# pmg1s3 register map
Vendor: Infineon Technologies; Series: PMG1S3; File version: 1.0
CPU: CM0PLUS r0p1, little endian, MPU, no FPU, VTOR, 2 interrupt priority bits, 32 interrupts
Registers are 32-bit, read-write, reset 0x0 unless marked. A register's access mark holds for its fields unless they carry their own. Offsets are from the block's base; [hi:lo] are bit positions; {n}, {i} and the like mark numbered series; 'fields as' and 'values as' point back to an identical list; <NAME> marks a mode.

## SCB0 — Serial Communications Block (SPI/UART/I2C)
Base 0x40220000
Same registers: SCB1 0x40230000, SCB2 0x40240000, SCB3 0x40250000, SCB4 0x40260000, SCB5 0x40270000, SCB6 0x40280000, SCB7 0x40290000
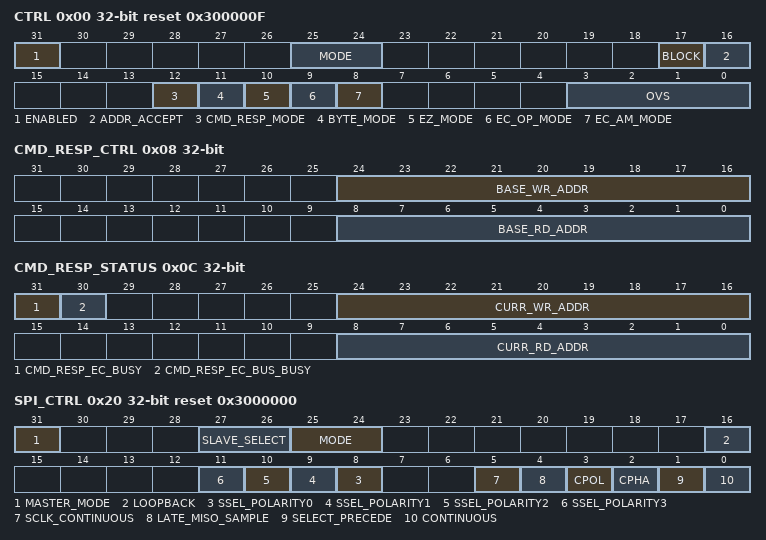
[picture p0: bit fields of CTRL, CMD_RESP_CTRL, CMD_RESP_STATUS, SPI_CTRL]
0x00 CTRL reset 0x300000F — Generic control register.
  [31] ENABLED — SCB block is enabled ('1') or not ('0'). The proper order in which to initialize SCB is as follows: - Program protocol specific information using SPI_CTRL, UART_CTRL (and UART_TX_CTRL and UART_RX_CTRL) or I2C_CTRL registers. This includes selection of a submode, master/slave functionality and transmitter/receiver functionality when applicable. - Program generic transmitter (TX_CTRL) and receiver (RX_CTRL) information. This includes enabling of the transmitter and receiver functionality. - Program transmitter FIFO (TX_FIFO_CTRL) and receiver FIFO (RX_FIFO_CTRL) information. - Program CTRL register to enable SCB, select the specific operation mode and oversampling factor. When this block is enabled, no control information should be changed. Changes should be made AFTER disabling this block, e.g. to modify the operation mode (from I2C to SPI) or to go from externally to internally clocked. The change takes effect after the block is re-enabled. Note that disabling the block will cause re-initialization of the design and associated state is lost (e.g. FIFO content).
  [25:24] MODE
    0=I2C (Inter-Integrated Circuits (I2C) mode.); 1=SPI (Serial Peripheral Interface (SPI) mode.); 2=UART (Universal Asynchronous Receiver/Transmitter (UART) mode.)
  [17] BLOCK — Only used in externally clocked mode. If the externally clocked logic and the internal CPU accesses to EZ memory coincide/collide, this bit determines whether the CPU access should block and result in bus wait states ('BLOCK is 1') or not (BLOCK is '0'). IF BLOCK is '0' and the accesses collide, CPU read operations return 0xffff:ffff and CPU write operations are ignored. Colliding accesses are registered as interrupt causes: INTR_TX.BLOCKED and INTR_RX.BLOCKED.
  [16] ADDR_ACCEPT — Determines whether a received matching address is accepted in the RX FIFO ('1') or not ('0'). In I2C mode, this field is used to allow the slave to put the received slave address or general call address in the RX FIFO. Note that a received matching address is put in the RX FIFO when this bit is '1' for both I2C read and write transfers. In multi-processor UART receiver mode, this field is used to allow the receiver to put the received address in the RX FIFO. Note: non-matching addresses are never put in the RX FIFO.
  [12] CMD_RESP_MODE
  [11] BYTE_MODE
  [10] EZ_MODE — Non EZ mode ('0') or EZ mode ('1'). In EZ mode, a meta protocol is applied to the serial interface protocol. This meta protocol adds meaning to the data frames transferred by the serial interface protocol: a data frame can represent a memory address, a write memory data element or a read memory data element. EZ mode is only used for synchronous serial interface protocols: SPI and I2C. In SPI mode, only Motorola submode (all Motorola modes: 0, 1, 2, 3) is supported and the transmitter should use continuous data frames; i.e. data frames not separated by slave deselection. This mode is only applicable to slave functionality. In EZ mode, the slave can read from and write to an addressable memory structure of 32 bytes. In EZ mode, data frames should 8-bit in size and should be transmitted and received with the Most Significant Bit (MSB) first. In UART mode this field should be '0'.
  [9] EC_OP_MODE — This field specifies the clocking for the SCB block '0': Internally clocked mode '1': externally clocked mode In internally clocked mode, the serial interface protocols run off the SCB clock. In externally clocked mode, the serial interface protocols run off the clock as provided by the serial interface. Externally clocked operation mode is only used for synchronous serial interface protocols (SPI and I2C) in slave mode AND EZ mode. In SPI mode, only Motorola submode (all Motorola modes: 0, 1, 2, 3) is supported. The maximum SPI slave, EZ mode bitrate is 48 Mbps (transmission and IO delays outside the IP will degrade the effective bitrate). In UART mode this field should be '0'.
  [8] EC_AM_MODE — This field specifies the clocking for the address matching (I2C) or slave selection detection logic (SPI) '0': Internally clocked mode '1': Externally clocked mode In internally clocked mode, the serial interface protocols run off the SCB clock. In externally clocked mode, the serial interface protocols run off the clock as provided by the serial interface. The clocking for the rest of the logic is determined by CTRL.EC_OP_MODE. Externally clocked mode is only used for synchronous serial interface protocols (SPI and I2C) in slave mode. In SPI mode, only Motorola submode (all Motorola modes: 0, 1, 2, 3) is supported. In UART mode this field should be '0'.
  [3:0] OVS
0x04 STATUS ro reset not defined — Generic status register.
  [0] EC_BUSY — Indicates whether the externally clocked logic is potentially accessing the EZ memory (this is only possible in EZ mode). This bit can be used by SW to determine whether it is safe to issue a SW access to the EZ memory (without bus wait states (a blocked SW access) or bus errors being generated). Note that the INTR_TX.BLOCKED and INTR_RX.BLOCKED interrupt causes are used to indicate whether a SW access was actually blocked by externally clocked logic.
0x08 CMD_RESP_CTRL — Command/response control register.
  [24:16] BASE_WR_ADDR — I2C/SPI write base address for CMD_RESP mode. At the start of a write transfer this BASE_WR_ADDR is copied to CMD_RESP_STATUS.CURR_WR_ADDR. This field should not be modified during ongoing bus transfers.
  [8:0] BASE_RD_ADDR — I2C/SPI read base address for CMD_RESP mode. At the start of a read transfer this BASE_RD_ADDR is copied to CMD_RESP_STATUS.CURR_RD_ADDR. This field should not be modified during ongoing bus transfers.
0x0C CMD_RESP_STATUS ro reset not defined — Command/response status register.
  [31] CMD_RESP_EC_BUSY
  [30] CMD_RESP_EC_BUS_BUSY — Indicates whether there is an ongoing bus transfer to the IP. '0': no ongoing bus transfer. '1': ongoing bus transfer. For SPI, the field is '1' when slave mode is selected. For I2C, the field is set to '1' at a I2C START/RESTART. In case of an address match, the field is set to '0' on a I2C STOP. In case of NO address match, the field is set to '0' after the failing address match.
  [24:16] CURR_WR_ADDR — I2C/SPI write current address for CMD_RESP mode. HW increments the field after a write access to the memory buffer. However, when the last memory buffer address is reached, the address is NOT incremented (but remains at the maximum memory buffer address). The field is used to determine how many bytes have been written (# bytes = CURR_WR_ADDR - CMD_RESP_CTRL.BASE_WR_ADDR). This field is reliable when there is no bus transfer. This field is potentially unreliable when there is a ongoing bus transfer, i.e. when CMD_RESP_EC_BUSY is '0', the field is reliable.
  [8:0] CURR_RD_ADDR — I2C/SPI read current address for CMD_RESP mode. HW increments the field after a read access to the memory buffer. However, when the last memory buffer address is reached, the address is NOT incremented (but remains at the maximum memory buffer address). The field is used to determine how many bytes have been read (# bytes = CURR_RD_ADDR - CMD_RESP_CTRL.BASE_RD_ADDR). This field is reliable when there is no bus transfer. This field is potentially unreliable when there is a ongoing bus transfer, i.e. when CMD_RESP_EC_BUSY is '0', the field is reliable.
0x20 SPI_CTRL reset 0x3000000 — SPI control register.
  [31] MASTER_MODE
  [27:26] SLAVE_SELECT — Selects one of the four outgoing SPI slave select signals: - 0: Slave 0, SPI_SELECT[0]. - 1: Slave 1, SPI_SELECT[1]. - 2: Slave 2, SPI_SELECT[2]. - 3: Slave 3, SPI_SELECT[3]. Only used in master mode. SCB block should be disabled when changes are made to this field.
  [25:24] MODE
    0=SPI_MOTOROLA (SPI Motorola submode. In master mode, when not transmitting data (SELECT is inactive), SCLK is stable at CPOL. In slave mode, when not selected, SCLK is ignored; i.e. it can be either stable or clocking. In master mode, when there is no data to transmit (TX FIFO is empty), SELECT is inactive.); 1=SPI_TI (SPI Texas Instruments submode. In master mode, when not transmitting data, SCLK is stable at '0'. In slave mode, when not selected, SCLK is ignored; i.e. it can be either stable or clocking. In master mode, when there is no data to transmit (TX FIFO is empty), SELECT is inactive; i.e. no pulse is generated.); 2=SPI_NS (SPI National Semiconductors submode. In master mode, when not transmitting data, SCLK is stable at '0'. In slave mode, when not selected, SCLK is ignored; i.e. it can be either stable or clocking. In master mode, when there is no data to transmit (TX FIFO is empty), SELECT is inactive.)
  [16] LOOPBACK — Local loopback control (does NOT affect the information on the pins). Only used in master mode. Not used in National Semiconductors submode. '0': No local loopback '1': the SPI master MISO line is connected to the SPI master MOSI line. In other words, in loopback mode the SPI master receives on MISO what it transmits on MOSI.
  [n+8] SSEL_POLARITY{n} (n=0..3)
  [5] SCLK_CONTINUOUS
  [4] LATE_MISO_SAMPLE — Changes the SCLK edge on which MISO is captured. Only used in master mode. When '0', the default applies ( for Motorola as determined by CPOL and CPHA, for Texas Instruments on the falling edge of SCLK and for National Semiconductors on the rising edge of SCLK). When '1', the alternate clock edge is used (which comes half a SPI SCLK period later). Late sampling addresses the round trip delay associated with transmitting SCLK from the master to the slave and transmitting MISO from the slave to the master.
  [3] CPOL
  [2] CPHA
  [1] SELECT_PRECEDE — Only used in SPI Texas Instruments' submode. When '1', the data frame start indication is a pulse on the Slave SELECT line that precedes the transfer of the first data frame bit. When '0', the data frame start indication is a pulse on the Slave SELECT line that coincides with the transfer of the first data frame bit.
  [0] CONTINUOUS — Continuous SPI data transfers enabled ('1') or not ('0'). This field is used in master mode. In slave mode, both continuous and non-continuous SPI data transfers are supported independent of this field. When continuous transfers are enabled individual data frame transfers are not necessarily separated by slave deselection (as indicated by the level or pulse on the SELECT line): if the TX FIFO has multiple data frames, data frames are send out without slave deselection. When continuous transfers are not enabled individual data frame transfers are always separated by slave deselection: independent of the availability of TX FIFO data frames, data frames are sent out with slave deselection.
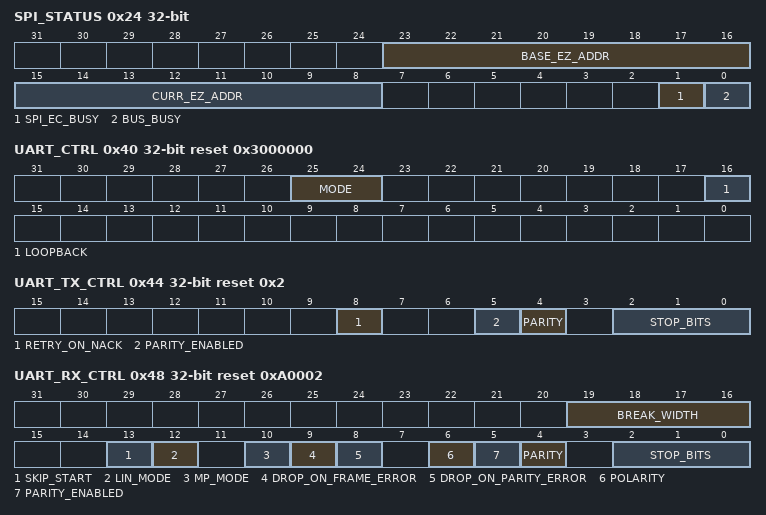
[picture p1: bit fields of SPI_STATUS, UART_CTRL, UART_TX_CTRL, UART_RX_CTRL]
0x24 SPI_STATUS ro reset not defined
  [23:16] BASE_EZ_ADDR — SPI base EZ address. Address as provided by a SPI write transfer. This field is only reliable in internally clocked mode. In externally clocked mode the field may be unreliable, as clock domain synchronization is not performed in the design.
  [15:8] CURR_EZ_ADDR — SPI current EZ address. Current address pointer. This field is only reliable in internally clocked mode. In externally clocked mode the field may be unreliable (during an ongoing transfer when SPI_EC_BUSY is '1'), as clock domain synchronization is not performed in the design.
  [1] SPI_EC_BUSY — Indicates whether the externally clocked logic is potentially accessing the EZ memory and/or updating BASE_ADDR or CURR_ADDR (this is only possible in EZ mode). This bit can be used by SW to determine whether BASE_ADDR and CURR_ADDR are reliable.
  [0] BUS_BUSY — SPI bus is busy. The bus is considered busy ('1') during an ongoing transaction. For Motorola and National submodes, the busy bit is '1', when the slave selection (low active) is activated. For TI submode, the busy bit is '1' from the time the preceding/coinciding slave select (high active) is activated for the first transmitted data frame, till the last MOSI/MISO bit of the last data frame is transmitted.
0x40 UART_CTRL reset 0x3000000 — UART control register.
  [25:24] MODE
    0=UART_STD (Standard UART submode.); 1=UART_SMARTCARD (SmartCard (ISO7816) submode. Support for negative acknowledgement (NACK) on the receiver side and retransmission on the transmitter side.); 2=UART_IRDA (Infrared Data Association (IrDA) submode. Return to Zero modulation scheme. In this mode, the oversampling factor should be 16, that is OVS is 15.)
  [16] LOOPBACK — Local loopback control (does NOT affect the information on the pins). 0: Loopback is not enabled 1: UART_TX is connected to UART_RX. UART_RTS is connected to UART_CTS. This allows a SCB UART transmitter to communicate with its receiver counterpart.
0x44 UART_TX_CTRL reset 0x2 — UART transmitter control register.
  [8] RETRY_ON_NACK — When '1', a data frame is retransmitted when a negative acknowledgement is received. Only applicable to the SmartCard submode.
  [5] PARITY_ENABLED — Parity generation enabled ('1') or not ('0'). Only applicable in standard UART submodes. In SmartCard submode, parity generation is always enabled through hardware. In IrDA submode, parity generation is always disabled through hardware
  [4] PARITY — Parity bit. When '0', the transmitter generates an even parity. When '1', the transmitter generates an odd parity. Only applicable in standard UART and SmartCard submodes.
  [2:0] STOP_BITS — Stop bits. STOP_BITS + 1 is the duration of the stop period in terms of halve bit periods. Valid range is [1, 7]; i.e. a stop period should last at least one bit period.
0x48 UART_RX_CTRL reset 0xA0002 — UART receiver control register.
  [19:16] BREAK_WIDTH
  [13] SKIP_START
  [12] LIN_MODE — Only applicable in standard UART submode. When '1', the receiver performs break detection and baud rate detection on the incoming data. First, break detection counts the amount of bit periods that have a line value of '0'. BREAK_WIDTH specifies the minimum required amount of bit periods. Successful break detection sets the INTR_RX.BREAK_DETECT interrupt cause to '1'. Second, baud rate detection counts the amount of peripheral clock periods that are use to receive the synchronization byte (0x55; least significant bit first). The count is available through UART_RX_STATUS.BR_COUNTER. Successful baud rate detection sets the INTR_RX.BAUD_DETECT interrupt cause to '1' (BR_COUNTER is reliable). This functionality is used to synchronize/refine the receiver clock to the transmitter clock. The receiver software can use the BR_COUNTER value to set the right IP clock (from the programmable clock IP) to guarantee successful receipt of the first LIN data frame (Protected Identifier Field) after the synchronization byte.
  [10] MP_MODE
  [9] DROP_ON_FRAME_ERROR — Behavior when an error is detected in a start or stop period. When '0', received data is sent to the RX FIFO. When '1', received data is dropped and lost.
  [8] DROP_ON_PARITY_ERROR — Behavior when a parity check fails. When '0', received data is sent to the RX FIFO. When '1', received data is dropped and lost. Only applicable in standard UART and SmartCard submodes (negatively acknowledged SmartCard data frames may be dropped with this field).
  [6] POLARITY — Inverts incoming RX line signal. Inversion is after local loopback. This functionality is intended for IrDA receiver functionality.
  [5] PARITY_ENABLED
  [4] PARITY
  [2:0] STOP_BITS
0x4C UART_RX_STATUS ro reset not defined — UART receiver status register.
  [11:0] BR_COUNTER — Amount of SCB clock periods that constitute the transmission of a 0x55 data frame (sent least significant bit first) as determined by the receiver. BR_COUNTER / 8 is the amount of SCB clock periods that constitute a bit period. This field has valid data when INTR_RX.BAUD_DETECT is set to '1'.
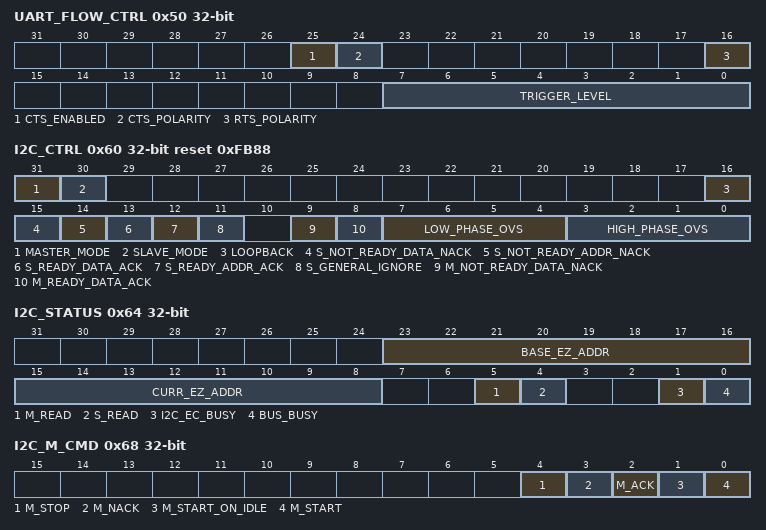
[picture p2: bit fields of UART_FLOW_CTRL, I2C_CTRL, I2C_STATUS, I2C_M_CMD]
0x50 UART_FLOW_CTRL — UART flow control register
  [25] CTS_ENABLED — Enable use of CTS input signal by the UART transmitter: '0': Disabled. The UART transmitter ignores the CTS input signal and transmits when a data frame is available for transmission in the TX FIFO or the TX shift register. '1': Enabled. The UART transmitter uses CTS input signal to qualify the transmission of data. It transmits when CTS input signal is active and a data frame is available for transmission in the TX FIFO or the TX shift register. If UART_CTRL.LOOPBACK is '1', the CTS input signal is driven by the RTS output signal locally in SCB (both signals are subjected to signal polarity changes as indicated by RTS_POLARITY and CTS_POLARITY).
  [24] CTS_POLARITY — Polarity of the CTS input signal '0': CTS is active low ; '1': CTS is active high;
  [16] RTS_POLARITY — Polarity of the RTS output signal: '0': RTS is active low; '1': RTS is active high; During SCB reset (Hibernate system power mode), RTS output signal is '1'. This represents an inactive state assuming an active low polarity.
  [7:0] TRIGGER_LEVEL — Trigger level. When the receiver FIFO has less entries than the amount of this field, a Ready To Send (RTS) output signal is activated. By setting this field to '0', flow control is effectively disabled (may be useful for debug purposes).
0x60 I2C_CTRL reset 0xFB88 — I2C control register.
  [31] MASTER_MODE
  [30] SLAVE_MODE
  [16] LOOPBACK — Local loopback control (does NOT affect the information on the pins). Only applicable in master/slave mode. When '0', no loopback When '1', loopback is enabled internally in the peripheral, and as a result unaffected by other I2C devices. This allows a SCB I2C peripheral to address itself.
  [15] S_NOT_READY_DATA_NACK — Only used when: - non EZ mode Functionality is as follows: - 1: a received data element byte the slave is immediately NACK'd when the receiver FIFO is full. - 0: clock stretching is performed (till the receiver FIFO is no longer full).
  [14] S_NOT_READY_ADDR_NACK — This field is used during an address match or general call address in internally clocked mode Only used when: - EC_AM_MODE is '0', EC_OP_MODE is '0', S_GENERAL_IGNORE is '0] and non EZ mode. Functionality is as follows: - 1: a received (matching) slave address is immediately NACK'd when the receiver FIFO is full. - 0: clock stretching is performed (till the receiver FIFO is no longer full). For externally clocked logic (EC_AM is '1') on an address match or general call address (and S_GENERAL_IGNORE is '0'). Only used when (NOT used when EC_AM is '1' and EC_OP is '1' and address match and EZ mode): - EC_AM is '1' and EC_OP is '0'. - EC_AM is '1' and general call address match. - EC_AM is '1' and non EZ mode. Functionality is as follows: - 1: a received (matching or general) slave address is always immediately NACK'd. There are two possibilities: 1). the SCB clock is available (in Active system power mode) and it handles the rest of the current transfer. In this case the I2C master will not observe the NACK. 2).SCB clock is not present (in DeepSleep system power mode). In this case the I2C master will observe the NACK and may retry the transfer in the future (which gives the internally clocked logic the time to wake up from DeepSleep system power mode). - 0: clock stretching is performed (till the SCB clock is available). The logic will handle the ongoing transfer as soon as the clock is enabled.
  [13] S_READY_DATA_ACK
  [12] S_READY_ADDR_ACK
  [11] S_GENERAL_IGNORE
  [9] M_NOT_READY_DATA_NACK
  [8] M_READY_DATA_ACK
  [7:4] LOW_PHASE_OVS — Serial I2C interface low phase oversampling factor. LOW_PHASE_OVS + 1 SCB clock periods constitute the low phase of a bit period. The valid range is [7, 15] with input signal median filtering and [6, 15] without input signal median filtering. The field is only used in master mode. In slave mode, the field is NOT used. However, there is a frequency requirement for the SCB clock wrt. the regular (no stretching) interface (IF) low time to guarantee functionally correct behavior. With input signal median filtering, the IF low time should be >= 8 SCB clock cycles and <= 16 IP clock cycles. Without input signal median filtering, the IF low time should be >= 7 SCB clock cycles and <= 16 SCB clock cycles.
  [3:0] HIGH_PHASE_OVS — Serial I2C interface high phase oversampling factor. HIGH_PHASE_OVS + 1 SCB clock periods constitute the high phase of a bit period. The valid range is [5, 15] with input signal median filtering and [4, 15] without input signal median filtering. The field is only used in master mode. In slave mode, the field is NOT used. However, there is a frequency requirement for the SCB clock wrt. the regular interface (IF) high time to guarantee functional correct behavior. With input signal median filtering, the IF high time should be >= 6 SCB clock cycles and <= 16 SCB clock cycles. Without input signal median filtering, the IF high time should be >= 5 SCB clock cycles and <= 16 SCB clock cycles.
0x64 I2C_STATUS ro (reset mask 0x31)
  [23:16] BASE_EZ_ADDR
  [15:8] CURR_EZ_ADDR
  [5] M_READ
  [4] S_READ
  [1] I2C_EC_BUSY
  [0] BUS_BUSY — I2C bus is busy. The bus is considered busy ('1'), from the time a START is detected or from the time the SCL line is '0'. The bus is considered idle ('0'), from the time a STOP is detected. If SCB block is disabled, BUS_BUSY is '0'. After enabling the block, it takes time for the BUS_BUSY to detect a busy bus. This time is the maximum high time of the SCL line. For a 100 kHz interface frequency, this maximum high time may last roughly 5 us (half a bit period). For single master systems, BUS_BUSY does not have to be used to detect an idle bus before a master starts a transfer using I2C_M_CMD.M_START (no bus collisions). For multi-master systems, BUS_BUSY can be used to detect an idle bus before a master starts a transfer using I2C_M_CMD.M_START_ON_IDLE (to prevent bus collisions).
0x68 I2C_M_CMD — I2C master command register.
  [4] M_STOP — When '1', attempt to transmit a STOP. When this action is performed, the hardware sets this field to '0'. I2C_M_CMD.M_START has a higher priority than this command: in situations where both a STOP and a REPEATED START could be transmitted, M_START takes precedence over M_STOP.
  [3] M_NACK — When '1', attempt to transmit a negative acknowledgement (NACK). When this action is performed, the hardware sets this field to '0'.
  [2] M_ACK — When '1', attempt to transmit an acknowledgement (ACK). When this action is performed, the hardware sets this field to '0'.
  [1] M_START_ON_IDLE — When '1', transmit a START as soon as the bus is idle (I2C_STATUS.BUS_BUSY is '0', note that BUSY has a default value of '0'). For bus idle detection the hardware relies on STOP detection. As a result, bus idle detection is only functional after at least one I2C bus transfer has been detected on the bus (default/reset value of BUSY is '0') . A START is only transmitted when the master state machine is in the default state. When this action is performed, the hardware sets this field to '0'.
  [0] M_START — When '1', transmit a START or REPEATED START. Whether a START or REPEATED START is transmitted depends on the state of the master state machine. A START is only transmitted when the master state machine is in the default state. A REPEATED START is transmitted when the master state machine is not in the default state, but is working on an ongoing transaction. The REPEATED START can only be transmitted after a NACK or ACK has been received for a transmitted data element or after a NACK has been transmitted for a received data element. When this action is performed, the hardware sets this field to '0'.
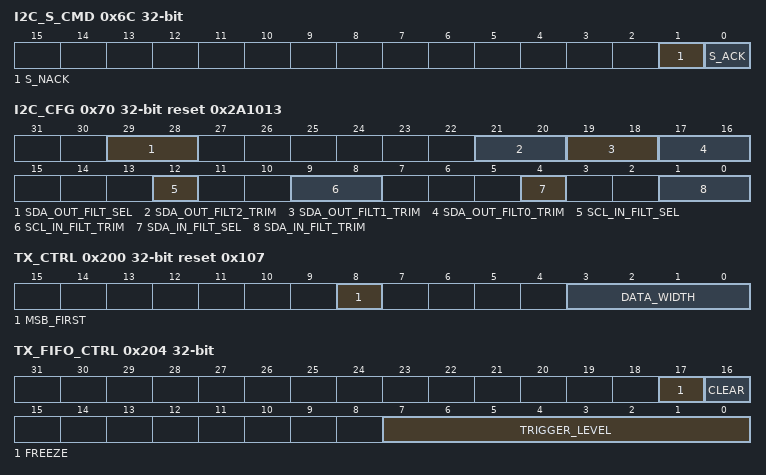
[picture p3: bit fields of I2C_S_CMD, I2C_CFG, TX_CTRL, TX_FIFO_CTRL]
0x6C I2C_S_CMD — I2C slave command register.
  [1] S_NACK — When '1', attempt to transmit a negative acknowledgement (NACK). When this action is performed, the hardware sets this field to '0'. In EZ mode, this field should be set to '0' (it is only to be used in non EZ mode). This command has a higher priority than I2C_S_CMD.S_ACK, I2C_CTRL.S_READY_ADDR_ACK or I2C_CTRL.S_READY_DATA_ACK.
  [0] S_ACK — When '1', attempt to transmit an acknowledgement (ACK). When this action is performed, the hardware sets this field to '0'. In EZ mode, this field should be set to '0' (it is only to be used in non EZ mode).
0x70 I2C_CFG reset 0x2A1013 — I2C configuration register.
  [29:28] SDA_OUT_FILT_SEL — Selection of cumulative filter delay on SDA output to meet tHD_DAT parameter '0': 0 ns. '1': 50 ns (filter 0 enabled). '2': 100 ns (filters 0 and 1 enabled). '3': 150 ns (filters 0, 1 and 2 enabled).
  [21:20] SDA_OUT_FILT2_TRIM — Trim settings for the 50ns delay filter on SDA output used to guarantee tHD_DAT I2C parameter. Default setting meets the I2C spec. Programmability available if required
  [19:18] SDA_OUT_FILT1_TRIM — Trim settings for the 50ns delay filter on SDA output used to guarantee tHD_DAT I2C parameter. Default setting meets the I2C spec. Programmability available if required
  [17:16] SDA_OUT_FILT0_TRIM — Trim settings for the 50ns delay filter on SDA output used to guarantee tHD_DAT I2C parameter. Default setting meets the I2C spec. Programmability available if required
  [12] SCL_IN_FILT_SEL — Enable for 50ns glitch filter on SCL input '0': 0 ns. '1: 50 ns (filter enabled).
  [9:8] SCL_IN_FILT_TRIM — Trim settings for the 50ns glitch filter on the SCL input. Default setting meets the I2C glitch rejections specs. Programmability available if required
  [4] SDA_IN_FILT_SEL — Enable for 50ns glitch filter on SDA input '0': 0 ns. '1: 50 ns (filter enabled).
  [1:0] SDA_IN_FILT_TRIM — Trim settings for the 50ns glitch filter on the SDA input. Default setting meets the I2C glitch rejections specs. Programmability available if required
0x200 TX_CTRL reset 0x107 — Transmitter control register.
  [8] MSB_FIRST — Least significant bit first ('0') or most significant bit first ('1'). For I2C, this field should be '1'.
  [3:0] DATA_WIDTH — Dataframe width. DATA_WIDTH + 1 is the amount of bits in a transmitted data frame. This number does not include start, parity and stop bits. For UART mode, the valid range is [3, 8]. For SPI, the valid range is [3, 15]. For I2C the only valid value is 7.
0x204 TX_FIFO_CTRL — Transmitter FIFO control register.
  [17] FREEZE — When '1', hardware reads from the transmitter FIFO do not remove FIFO entries. Freeze will not advance the TX FIFO read pointer.
  [16] CLEAR — When '1', the transmitter FIFO and transmitter shift register are cleared/invalidated. Invalidation will last for as long as this field is '1'. If a quick clear/invalidation is required, the field should be set to '1' and be followed by a set to '0'. If a clear/invalidation is required for an extended time period, the field should be set to '1' during the complete time period.
  [7:0] TRIGGER_LEVEL — Trigger level. When the transmitter FIFO has less entries than the number of this field, a transmitter trigger event INTR_TX.TRIGGER is generated.
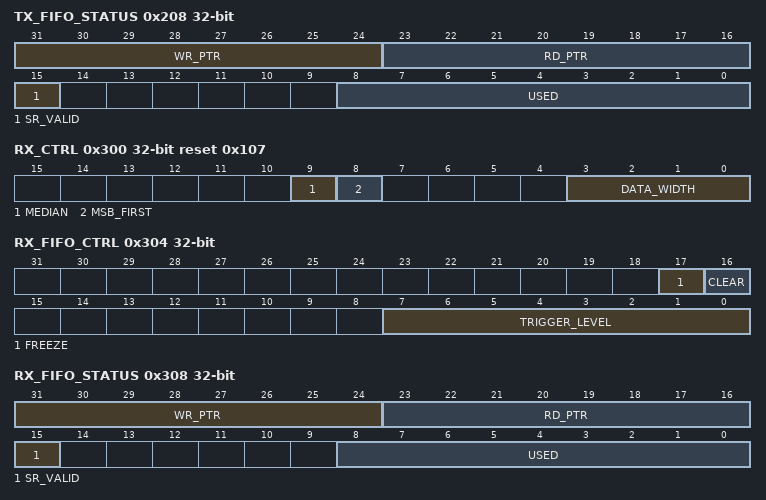
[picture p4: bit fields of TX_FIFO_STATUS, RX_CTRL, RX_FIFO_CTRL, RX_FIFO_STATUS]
0x208 TX_FIFO_STATUS ro — Transmitter FIFO status register.
  [31:24] WR_PTR — FIFO write pointer: FIFO location at which a new data frame is written.
  [23:16] RD_PTR — FIFO read pointer: FIFO location from which a data frame is read by the hardware.
  [15] SR_VALID — Indicates whether the TX shift registers holds a valid data frame ('1') or not ('0'). The shift register can be considered the top of the TX FIFO (the data frame is not included in the USED field of the TX FIFO). The shift register is a working register and holds the data frame that is currently transmitted (when the protocol state machine is transmitting a data frame) or the data frame that is transmitted next (when the protocol state machine is not transmitting a data frame).
  [8:0] USED — Amount of entries in the transmitter FIFO. The value of this field ranges from 0 to FF_DATA_NR (EZ_DATA_NR/2).
0x240 TX_FIFO_WR wo — Transmitter FIFO write register.
  [15:0] DATA — Data frame written into the transmitter FIFO. Behavior is similar to that of a PUSH operation. Note that when CTRL.BYTE_MODE is '1', only DATA[7:0] are used. A write to a full TX FIFO sets INTR_TX.OVERFLOW to '1'.
0x300 RX_CTRL reset 0x107 — Receiver control register.
  [9] MEDIAN — Median filter. When '1', a digital 3 taps median filter is performed on input interface lines. This filter should reduce the susceptibility to errors. However, its requires higher oversampling values. For UART IrDA submode, this field should always be '1'.
  [8] MSB_FIRST — Least significant bit first ('0') or most significant bit first ('1'). For I2C, this field should be '1'.
  [3:0] DATA_WIDTH — Dataframe width. DATA_WIDTH + 1 is the expected amount of bits in received data frame. This number does not include start, parity and stop bits. For UART mode, the valid range is [3, 8]. For SPI, the valid range is [3, 15]. For I2C the only valid value is 7. In EZ mode (for both SPI and I2C), the only valid value is 7.
0x304 RX_FIFO_CTRL — Receiver FIFO control register.
  [17] FREEZE — When '1', hardware writes to the receiver FIFO have no effect. Freeze will not advance the RX FIFO write pointer.
  [16] CLEAR — When '1', the receiver FIFO and receiver shift register are cleared/invalidated. Invalidation will last for as long as this field is '1'. If a quick clear/invalidation is required, the field should be set to '1' and be followed by a set to '0'. If a clear/invalidation is required for an extended time period, the field should be set to '1' during the complete time period.
  [7:0] TRIGGER_LEVEL — Trigger level. When the receiver FIFO has more entries than the number of this field, a receiver trigger event INTR_RX.TRIGGER is generated.
0x308 RX_FIFO_STATUS ro — Receiver FIFO status register.
  [31:24] WR_PTR — FIFO write pointer: FIFO location at which a new data frame is written by the hardware.
  [23:16] RD_PTR — FIFO read pointer: FIFO location from which a data frame is read.
  [15] SR_VALID — Indicates whether the RX shift registers holds a (partial) valid data frame ('1') or not ('0'). The shift register can be considered the bottom of the RX FIFO (the data frame is not included in the USED field of the RX FIFO). The shift register is a working register and holds the data frame that is currently being received (when the protocol state machine is receiving a data frame).
  [8:0] USED — Amount of entries in the receiver FIFO. The value of this field ranges from 0 to FF_DATA_NR (EZ_DATA_NR/2).
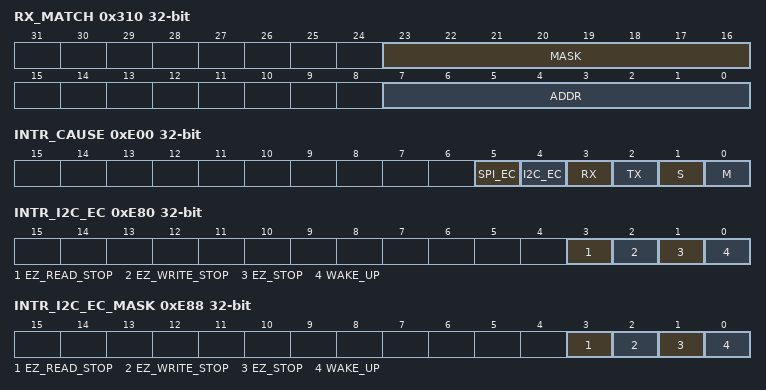
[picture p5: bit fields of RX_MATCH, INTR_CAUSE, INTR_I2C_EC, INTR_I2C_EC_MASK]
0x310 RX_MATCH — Slave address and mask register.
  [23:16] MASK — Slave device address mask. This field is a mask that specifies which of the slave address bits take part in the matching. MATCH = ((ADDR & MASK) == ('slave address' & MASK)).
  [7:0] ADDR
0x340 RX_FIFO_RD ro reset not defined — Receiver FIFO read register.
  [15:0] DATA — Data read from the receiver FIFO. Reading a data frame will remove the data frame from the FIFO; i.e. behavior is similar to that of a POP operation. Note that when CTRL.BYTE_MODE is '1', only DATA[7:0] are used. A read from an empty RX FIFO sets INTR_RX.UNDERFLOW to '1'. When this register is read through the debugger, the data frame will not be removed from the FIFO. Similar in operation to RX_FIFO_RD_SILENT
0x344 RX_FIFO_RD_SILENT ro reset not defined — Receiver FIFO read register.
  [15:0] DATA — Data read from the receiver FIFO. Reading a data frame will NOT remove the data frame from the FIFO; i.e. behavior is similar to that of a PEEK operation. Note that when CTRL.BYTE_MODE is '1', only DATA[7:0] are used. A read from an empty RX FIFO sets INTR_RX.UNDERFLOW to '1'.
0xE00 INTR_CAUSE ro — Active clocked interrupt signal register
  [5] SPI_EC — Externally clocked SPI interrupt active ('interrupt_spi_ec'): INTR_SPI_EC_MASKED != 0.
  [4] I2C_EC — Externally clock I2C interrupt active ('interrupt_i2c_ec'): INTR_I2C_EC_MASKED != 0.
  [3] RX — Receiver interrupt active ('interrupt_rx'): INTR_RX_MASKED != 0.
  [2] TX — Transmitter interrupt active ('interrupt_tx'): INTR_TX_MASKED != 0.
  [1] S — Slave interrupt active ('interrupt_slave'): INTR_S_MASKED != 0.
  [0] M — Master interrupt active ('interrupt_master'): INTR_M_MASKED != 0.
0xE80 INTR_I2C_EC — Externally clocked I2C interrupt request register
  [3] EZ_READ_STOP write-1-clears — STOP detection after a read transfer occurred. Activated on the end of a read transfer (I2C STOP). This event is an indication that a buffer memory location has been read from. Only available for a slave request with an address match, in EZ and CMD_RESP modes, when CTRL.EC_OP_MODE is '1'.
  [2] EZ_WRITE_STOP write-1-clears — STOP detection after a write transfer occurred. Activated on the end of a write transfer (I2C STOP). This event is an indication that a buffer memory location has been written to. For EZ mode: a transfer that only writes the base address does NOT activate this event. Only available for a slave request with an address match, in EZ and CMD_RESP modes, when CTRL.EC_OP_MODE is '1'.
  [1] EZ_STOP write-1-clears — STOP detection. Activated on the end of a every transfer (I2C STOP). Only available for a slave request with an address match, in EZ and CMD_RESP modes, when CTRL.EC_OP_MODE is '1'.
  [0] WAKE_UP write-1-clears — Wake up request. Active on incoming slave request (with address match). Only used when CTRL.EC_AM_MODE is '1'.
0xE88 INTR_I2C_EC_MASK — Externally clocked I2C interrupt mask register
  [3] EZ_READ_STOP — Mask bit for corresponding bit in interrupt request register.
  [2] EZ_WRITE_STOP — Mask bit for corresponding bit in interrupt request register.
  [1] EZ_STOP — Mask bit for corresponding bit in interrupt request register.
  [0] WAKE_UP — Mask bit for corresponding bit in interrupt request register.
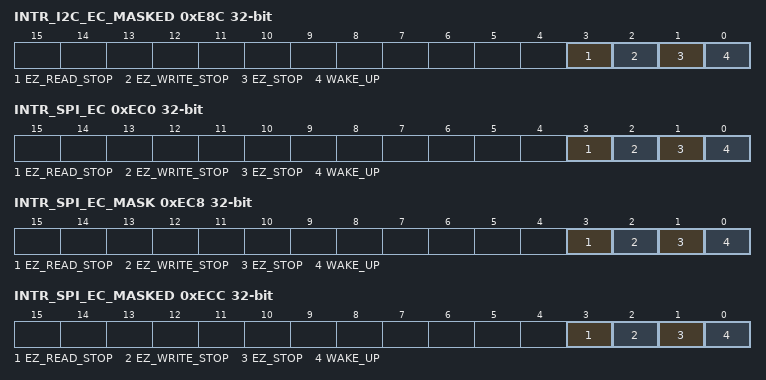
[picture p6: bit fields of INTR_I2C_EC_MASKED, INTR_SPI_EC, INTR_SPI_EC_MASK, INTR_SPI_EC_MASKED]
0xE8C INTR_I2C_EC_MASKED ro — Externally clocked I2C interrupt masked register
  [3] EZ_READ_STOP — Logical and of corresponding request and mask bits.
  [2] EZ_WRITE_STOP — Logical and of corresponding request and mask bits.
  [1] EZ_STOP — Logical and of corresponding request and mask bits.
  [0] WAKE_UP — Logical and of corresponding request and mask bits.
0xEC0 INTR_SPI_EC — Externally clocked SPI interrupt request register
  [3] EZ_READ_STOP write-1-clears — STOP detection after a read transfer occurred. Activated on the end of a read transfer (SPI deselection). This event is an indication that a buffer memory location has been read from. Only used in EZ and CMD_RESP modes and when CTRL.EC_OP_MODE is '1'.
  [2] EZ_WRITE_STOP write-1-clears — STOP detection after a write transfer occurred. Activated on the end of a write transfer (SPI deselection). This event is an indication that a buffer memory location has been written to. For EZ mode: a transfer that only writes the base address does NOT activate this event. Only used in EZ and CMD_RESP modes and when CTRL.EC_OP_MODE is '1'.
  [1] EZ_STOP write-1-clears — STOP detection. Activated on the end of a every transfer (SPI deselection). Only available in EZ and CMD_RESP mode and when CTRL.EC_OP_MODE is '1'.
  [0] WAKE_UP write-1-clears — Wake up request. Active on incoming slave request when externally clocked selection is '1'. Only used when CTRL.EC_AM_MODE is '1'.
0xEC8 INTR_SPI_EC_MASK — Externally clocked SPI interrupt mask register
  fields as INTR_I2C_EC_MASK
0xECC INTR_SPI_EC_MASKED ro — Externally clocked SPI interrupt masked register
  fields as INTR_I2C_EC_MASKED
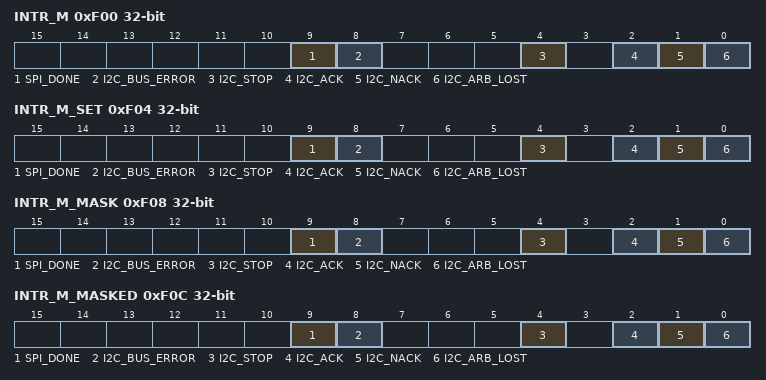
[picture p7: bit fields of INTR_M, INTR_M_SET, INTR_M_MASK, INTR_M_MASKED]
0xF00 INTR_M — Master interrupt request register.
  [9] SPI_DONE write-1-clears — SPI master transfer done event: all data frames in the transmit FIFO are sent and the transmit FIFO and shift register are empty.
  [8] I2C_BUS_ERROR write-1-clears — I2C master bus error (unexpected detection of START or STOP condition).
  [4] I2C_STOP write-1-clears — I2C master STOP. Set to '1', when the master has transmitted a STOP.
  [2] I2C_ACK write-1-clears — I2C master acknowledgement. Set to '1', when the master receives a ACK (typically after the master transmitted the slave address or TX data).
  [1] I2C_NACK write-1-clears — I2C master negative acknowledgement. Set to '1', when the master receives a NACK (typically after the master transmitted the slave address or TX data).
  [0] I2C_ARB_LOST write-1-clears — I2C master lost arbitration: the value driven by the master on the SDA line is not the same as the value observed on the SDA line.
0xF04 INTR_M_SET — Master interrupt set request register
  [9] SPI_DONE write-1-sets — Write with '1' to set corresponding bit in interrupt request register.
  [8] I2C_BUS_ERROR write-1-sets — Write with '1' to set corresponding bit in interrupt request register.
  [4] I2C_STOP write-1-sets — Write with '1' to set corresponding bit in interrupt request register.
  [2] I2C_ACK write-1-sets — Write with '1' to set corresponding bit in interrupt request register.
  [1] I2C_NACK write-1-sets — Write with '1' to set corresponding bit in interrupt request register.
  [0] I2C_ARB_LOST write-1-sets — Write with '1' to set corresponding bit in interrupt request register.
0xF08 INTR_M_MASK — Master interrupt mask register.
  [9] SPI_DONE — Mask bit for corresponding bit in interrupt request register.
  [8] I2C_BUS_ERROR — Mask bit for corresponding bit in interrupt request register.
  [4] I2C_STOP — Mask bit for corresponding bit in interrupt request register.
  [2] I2C_ACK — Mask bit for corresponding bit in interrupt request register.
  [1] I2C_NACK — Mask bit for corresponding bit in interrupt request register.
  [0] I2C_ARB_LOST — Mask bit for corresponding bit in interrupt request register.
0xF0C INTR_M_MASKED ro — Master interrupt masked request register
  [9] SPI_DONE — Logical and of corresponding request and mask bits.
  [8] I2C_BUS_ERROR — Logical and of corresponding request and mask bits.
  [4] I2C_STOP — Logical and of corresponding request and mask bits.
  [2] I2C_ACK — Logical and of corresponding request and mask bits.
  [1] I2C_NACK — Logical and of corresponding request and mask bits.
  [0] I2C_ARB_LOST — Logical and of corresponding request and mask bits.
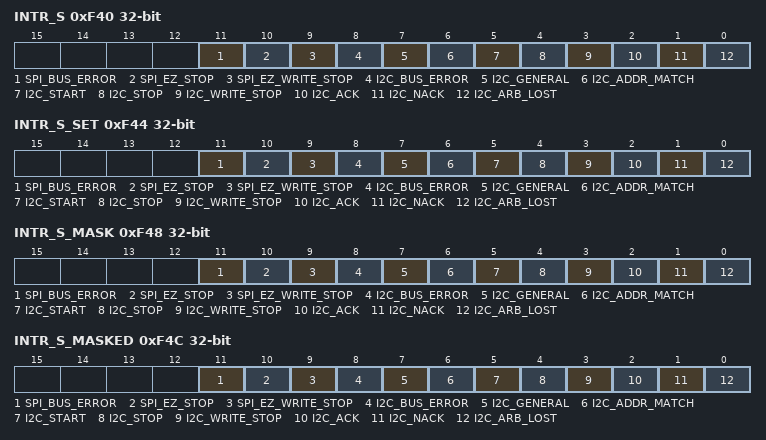
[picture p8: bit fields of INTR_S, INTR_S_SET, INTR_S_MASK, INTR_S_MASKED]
0xF40 INTR_S — Slave interrupt request register.
  [11] SPI_BUS_ERROR write-1-clears
  [10] SPI_EZ_STOP write-1-clears
  [9] SPI_EZ_WRITE_STOP write-1-clears
  [8] I2C_BUS_ERROR write-1-clears
  [7] I2C_GENERAL write-1-clears
  [6] I2C_ADDR_MATCH write-1-clears
  [5] I2C_START write-1-clears — I2C slave START received. Set to '1', when START or REPEATED START event is detected. In the case of externally clocked address matching (CTRL.EC_AM_MODE is '1') AND clock stretching is performed (I2C_CTRL.S_NOT_READY_ADDR_NACK is '0'), this field is NOT set. The Firmware should use INTR_S_EC.WAKE_UP, INTR_S.I2C_ADDR_MATCH and INTR_S.I2C_GENERAL.
  [4] I2C_STOP write-1-clears
  [3] I2C_WRITE_STOP write-1-clears
  [2] I2C_ACK write-1-clears
  [1] I2C_NACK write-1-clears
  [0] I2C_ARB_LOST write-1-clears — I2C slave lost arbitration: the value driven on the SDA line is not the same as the value observed on the SDA line (while the SCL line is '1'). This should not occur, it represents erroneous I2C bus behavior. In case of lost arbitration, the I2C slave state machine aborts the ongoing transfer. The Firmware may decide to clear the TX and RX FIFOs in case of this error.
0xF44 INTR_S_SET — Slave interrupt set request register.
  [11] SPI_BUS_ERROR write-1-sets — Write with '1' to set corresponding bit in interrupt request register.
  [10] SPI_EZ_STOP write-1-sets — Write with '1' to set corresponding bit in interrupt request register.
  [9] SPI_EZ_WRITE_STOP write-1-sets — Write with '1' to set corresponding bit in interrupt request register.
  [8] I2C_BUS_ERROR write-1-sets — Write with '1' to set corresponding bit in interrupt request register.
  [7] I2C_GENERAL write-1-sets — Write with '1' to set corresponding bit in interrupt request register.
  [6] I2C_ADDR_MATCH write-1-sets — Write with '1' to set corresponding bit in interrupt request register.
  [5] I2C_START write-1-sets — Write with '1' to set corresponding bit in interrupt request register.
  [4] I2C_STOP write-1-sets — Write with '1' to set corresponding bit in interrupt request register.
  [3] I2C_WRITE_STOP write-1-sets — Write with '1' to set corresponding bit in interrupt request register.
  [2] I2C_ACK write-1-sets — Write with '1' to set corresponding bit in interrupt request register.
  [1] I2C_NACK write-1-sets — Write with '1' to set corresponding bit in interrupt request register.
  [0] I2C_ARB_LOST write-1-sets — Write with '1' to set corresponding bit in interrupt request register.
0xF48 INTR_S_MASK — Slave interrupt mask register.
  [11] SPI_BUS_ERROR — Mask bit for corresponding bit in interrupt request register.
  [10] SPI_EZ_STOP — Mask bit for corresponding bit in interrupt request register.
  [9] SPI_EZ_WRITE_STOP — Mask bit for corresponding bit in interrupt request register.
  [8] I2C_BUS_ERROR — Mask bit for corresponding bit in interrupt request register.
  [7] I2C_GENERAL — Mask bit for corresponding bit in interrupt request register.
  [6] I2C_ADDR_MATCH — Mask bit for corresponding bit in interrupt request register.
  [5] I2C_START — Mask bit for corresponding bit in interrupt request register.
  [4] I2C_STOP — Mask bit for corresponding bit in interrupt request register.
  [3] I2C_WRITE_STOP — Mask bit for corresponding bit in interrupt request register.
  [2] I2C_ACK — Mask bit for corresponding bit in interrupt request register.
  [1] I2C_NACK — Mask bit for corresponding bit in interrupt request register.
  [0] I2C_ARB_LOST — Mask bit for corresponding bit in interrupt request register.
0xF4C INTR_S_MASKED ro — Slave interrupt masked request register
  [11] SPI_BUS_ERROR — Logical and of corresponding request and mask bits.
  [10] SPI_EZ_STOP — Logical and of corresponding request and mask bits.
  [9] SPI_EZ_WRITE_STOP — Logical and of corresponding request and mask bits.
  [8] I2C_BUS_ERROR — Logical and of corresponding request and mask bits.
  [7] I2C_GENERAL — Logical and of corresponding request and mask bits.
  [6] I2C_ADDR_MATCH — Logical and of corresponding request and mask bits.
  [5] I2C_START — Logical and of corresponding request and mask bits.
  [4] I2C_STOP — Logical and of corresponding request and mask bits.
  [3] I2C_WRITE_STOP — Logical and of corresponding request and mask bits.
  [2] I2C_ACK — Logical and of corresponding request and mask bits.
  [1] I2C_NACK — Logical and of corresponding request and mask bits.
  [0] I2C_ARB_LOST — Logical and of corresponding request and mask bits.
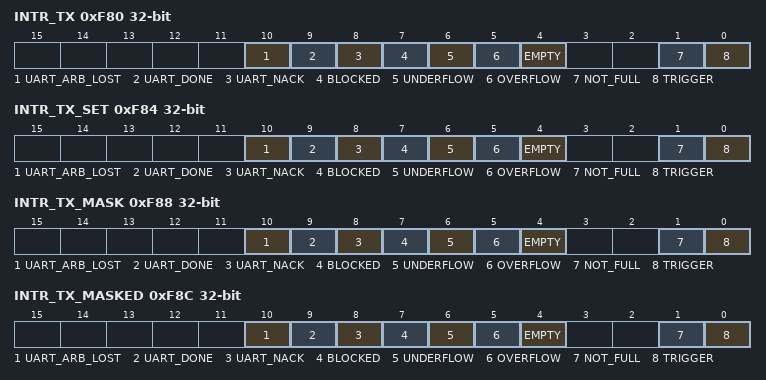
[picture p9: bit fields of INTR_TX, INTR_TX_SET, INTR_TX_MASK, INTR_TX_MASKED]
0xF80 INTR_TX — Transmitter interrupt request register.
  [10] UART_ARB_LOST write-1-clears
  [9] UART_DONE write-1-clears
  [8] UART_NACK write-1-clears
  [7] BLOCKED write-1-clears — SW cannot get access to the EZ memory (EZ data access), due to an externally clocked EZ access. This may happen when STATUS.EC_BUSY is '1'.
  [6] UNDERFLOW write-1-clears — Attempt to read from an empty TX FIFO. This happens when SCB is ready to transfer data and EMPTY is '1'. Only used in FIFO mode.
  [5] OVERFLOW write-1-clears
  [4] EMPTY write-1-clears
  [1] NOT_FULL write-1-clears
  [0] TRIGGER write-1-clears
0xF84 INTR_TX_SET — Transmitter interrupt set request register
  [10] UART_ARB_LOST write-1-sets — Write with '1' to set corresponding bit in interrupt request register.
  [9] UART_DONE write-1-sets — Write with '1' to set corresponding bit in interrupt request register.
  [8] UART_NACK write-1-sets — Write with '1' to set corresponding bit in interrupt request register.
  [7] BLOCKED write-1-sets — Write with '1' to set corresponding bit in interrupt request register.
  [6] UNDERFLOW write-1-sets — Write with '1' to set corresponding bit in interrupt request register.
  [5] OVERFLOW write-1-sets — Write with '1' to set corresponding bit in interrupt request register.
  [4] EMPTY write-1-sets — Write with '1' to set corresponding bit in interrupt request register.
  [1] NOT_FULL write-1-sets — Write with '1' to set corresponding bit in interrupt request register.
  [0] TRIGGER write-1-sets — Write with '1' to set corresponding bit in interrupt request register.
0xF88 INTR_TX_MASK — Transmitter interrupt mask register.
  [10] UART_ARB_LOST — Mask bit for corresponding bit in interrupt request register.
  [9] UART_DONE — Mask bit for corresponding bit in interrupt request register.
  [8] UART_NACK — Mask bit for corresponding bit in interrupt request register.
  [7] BLOCKED — Mask bit for corresponding bit in interrupt request register.
  [6] UNDERFLOW — Mask bit for corresponding bit in interrupt request register.
  [5] OVERFLOW — Mask bit for corresponding bit in interrupt request register.
  [4] EMPTY — Mask bit for corresponding bit in interrupt request register.
  [1] NOT_FULL — Mask bit for corresponding bit in interrupt request register.
  [0] TRIGGER — Mask bit for corresponding bit in interrupt request register.
0xF8C INTR_TX_MASKED ro — Transmitter interrupt masked request register
  [10] UART_ARB_LOST — Logical and of corresponding request and mask bits.
  [9] UART_DONE — Logical and of corresponding request and mask bits.
  [8] UART_NACK — Logical and of corresponding request and mask bits.
  [7] BLOCKED — Logical and of corresponding request and mask bits.
  [6] UNDERFLOW — Logical and of corresponding request and mask bits.
  [5] OVERFLOW — Logical and of corresponding request and mask bits.
  [4] EMPTY — Logical and of corresponding request and mask bits.
  [1] NOT_FULL — Logical and of corresponding request and mask bits.
  [0] TRIGGER — Logical and of corresponding request and mask bits.
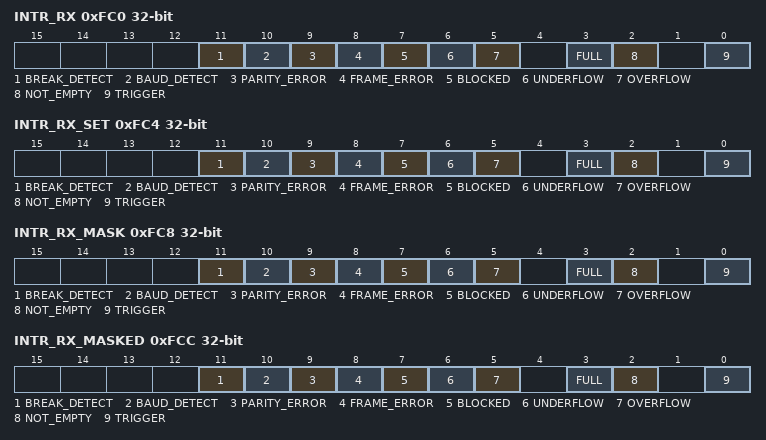
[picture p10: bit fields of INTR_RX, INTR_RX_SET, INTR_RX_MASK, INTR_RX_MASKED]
0xFC0 INTR_RX — Receiver interrupt request register.
  [11] BREAK_DETECT write-1-clears
  [10] BAUD_DETECT write-1-clears
  [9] PARITY_ERROR write-1-clears
  [8] FRAME_ERROR write-1-clears
  [7] BLOCKED write-1-clears — SW cannot get access to the EZ memory (EZ_DATA accesses), due to an externally clocked EZ access. This may happen when STATUS.EC_BUSY is '1'.
  [6] UNDERFLOW write-1-clears
  [5] OVERFLOW write-1-clears
  [3] FULL write-1-clears
  [2] NOT_EMPTY write-1-clears
  [0] TRIGGER write-1-clears
0xFC4 INTR_RX_SET — Receiver interrupt set request register.
  [11] BREAK_DETECT write-1-sets — Write with '1' to set corresponding bit in interrupt status register.
  [10] BAUD_DETECT write-1-sets — Write with '1' to set corresponding bit in interrupt status register.
  [9] PARITY_ERROR write-1-sets — Write with '1' to set corresponding bit in interrupt status register.
  [8] FRAME_ERROR write-1-sets — Write with '1' to set corresponding bit in interrupt status register.
  [7] BLOCKED write-1-sets — Write with '1' to set corresponding bit in interrupt status register.
  [6] UNDERFLOW write-1-sets — Write with '1' to set corresponding bit in interrupt status register.
  [5] OVERFLOW write-1-sets — Write with '1' to set corresponding bit in interrupt status register.
  [3] FULL write-1-sets — Write with '1' to set corresponding bit in interrupt status register.
  [2] NOT_EMPTY write-1-sets — Write with '1' to set corresponding bit in interrupt status register.
  [0] TRIGGER write-1-sets — Write with '1' to set corresponding bit in interrupt request register.
0xFC8 INTR_RX_MASK — Receiver interrupt mask register.
  [11] BREAK_DETECT — Mask bit for corresponding bit in interrupt request register.
  [10] BAUD_DETECT — Mask bit for corresponding bit in interrupt request register.
  [9] PARITY_ERROR — Mask bit for corresponding bit in interrupt request register.
  [8] FRAME_ERROR — Mask bit for corresponding bit in interrupt request register.
  [7] BLOCKED — Mask bit for corresponding bit in interrupt request register.
  [6] UNDERFLOW — Mask bit for corresponding bit in interrupt request register.
  [5] OVERFLOW — Mask bit for corresponding bit in interrupt request register.
  [3] FULL — Mask bit for corresponding bit in interrupt request register.
  [2] NOT_EMPTY — Mask bit for corresponding bit in interrupt request register.
  [0] TRIGGER — Mask bit for corresponding bit in interrupt request register.
0xFCC INTR_RX_MASKED ro — Receiver interrupt masked request register
  [11] BREAK_DETECT — Logical and of corresponding request and mask bits.
  [10] BAUD_DETECT — Logical and of corresponding request and mask bits.
  [9] PARITY_ERROR — Logical and of corresponding request and mask bits.
  [8] FRAME_ERROR — Logical and of corresponding request and mask bits.
  [7] BLOCKED — Logical and of corresponding request and mask bits.
  [6] UNDERFLOW — Logical and of corresponding request and mask bits.
  [5] OVERFLOW — Logical and of corresponding request and mask bits.
  [3] FULL — Logical and of corresponding request and mask bits.
  [2] NOT_EMPTY — Logical and of corresponding request and mask bits.
  [0] TRIGGER — Logical and of corresponding request and mask bits.

## Notices in the file
(c) 2016-2026, Infineon Technologies AG or an affiliate of
Infineon Technologies AG.
SPDX-License-Identifier: Apache-2.0
Licensed under the Apache License, Version 2.0 (the "License");
you may not use this file except in compliance with the License.
You may obtain a copy of the License at
http://www.apache.org/licenses/LICENSE-2.0
Unless required by applicable law or agreed to in writing, software
distributed under the License is distributed on an "AS IS" BASIS,
WITHOUT WARRANTIES OR CONDITIONS OF ANY KIND, either express or implied.
See the License for the specific language governing permissions and
limitations under the License.
